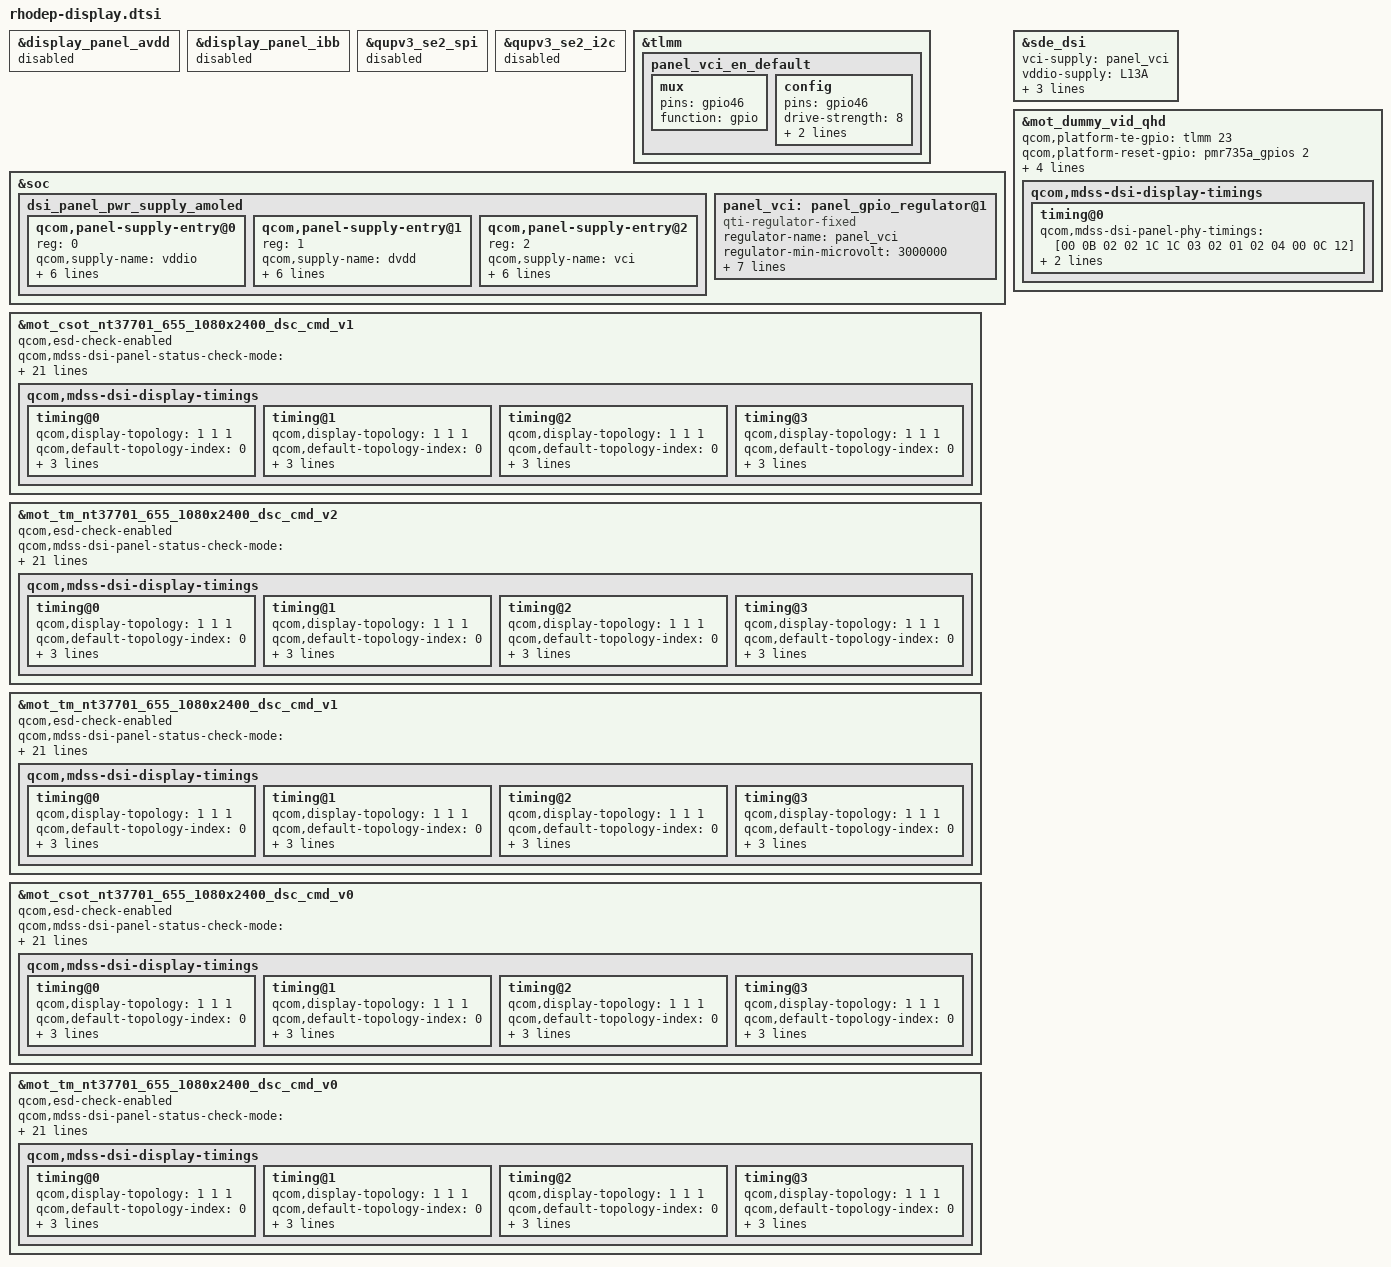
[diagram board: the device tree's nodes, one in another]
#include "dsi-panel-mot-csot-nt37701-655-1080x2400-dsc-cmd-common.dtsi"
#include "dsi-panel-mot-csot-nt37701-655-1080x2400-dsc-cmd-common-v1.dtsi"
#include "dsi-panel-mot-tianma-nt37701-655-1080x2400-dsc-cmd-common.dtsi"
#include "dsi-panel-mot-tianma-nt37701-655-1080x2400-dsc-cmd-common-v1.dtsi"
#include "dsi-panel-mot-tianma-nt37701-655-1080x2400-dsc-cmd-common-v2.dtsi"
#include "dsi-panel-mot-dummy-qhd-video.dtsi"

&display_panel_avdd {
	/delete-property/ gpio;
	/delete-property/ pinctrl-0;
};

&display_panel_avdd {
	status = "disabled";
};

&display_panel_ibb {
	status = "disabled";
};

&qupv3_se2_spi {
	status = "disabled";
};

&qupv3_se2_i2c {
	status = "disabled";
};

&tlmm {
	panel_vci_en_default: panel_vci_en_default {
		mux {
			pins = "gpio46";
			function = "gpio";
		};

		config {
			pins = "gpio46";
			drive-strength = <8>;
			bias-disable = <0>;
			output-high;
		};
	};
};

&soc {
	dsi_panel_pwr_supply_amoled: dsi_panel_pwr_supply_amoled {
		#address-cells = <1>;
		#size-cells = <0>;

		qcom,panel-supply-entry@0 {
			reg = <0>;
			qcom,supply-name = "vddio";
			qcom,supply-min-voltage = <1800000>;
			qcom,supply-max-voltage = <1800000>;
			qcom,supply-enable-load = <60700>;
			qcom,supply-disable-load = <80>;
		        qcom,supply-post-on-sleep = <2>;
			qcom,supply-post-off-sleep = <0>;
		};

		qcom,panel-supply-entry@1 {
			reg = <1>;
			qcom,supply-name = "dvdd";
			qcom,supply-min-voltage = <1250000>;
			qcom,supply-max-voltage = <1250000>;
			qcom,supply-enable-load = <60700>;
			qcom,supply-disable-load = <10>;
		        qcom,supply-post-on-sleep = <2>;
		        qcom,supply-post-off-sleep = <2>;
		};

		qcom,panel-supply-entry@2 {
			reg = <2>;
			qcom,supply-name = "vci";
			qcom,supply-min-voltage = <3000000>;
			qcom,supply-max-voltage = <3000000>;
			qcom,supply-enable-load = <30000>;
			qcom,supply-disable-load = <0>;
			qcom,supply-post-on-sleep = <0>;
			qcom,supply-post-off-sleep = <2>;
		};
	};

	panel_vci: panel_gpio_regulator@1 {
		compatible = "qti-regulator-fixed";
		regulator-name = "panel_vci";
		regulator-min-microvolt = <3000000>;
		regulator-max-microvolt = <3000000>;
		regulator-enable-ramp-delay = <233>;
		gpio = <&tlmm 46 0>;
		enable-active-high;
		regulator-boot-on;
		proxy-supply = <&panel_vci>;
		pinctrl-names = "default";
		pinctrl-0 = <&panel_vci_en_default>;
	};
};

&sde_dsi {
	/delete-property/ lab-supply;
	/delete-property/ ibb-supply;
	/delete-property/ vddio-supply;
	/delete-property/ qcom,dsi-default-panel;
	/delete-property/ avdd-supply;

	vci-supply = <&panel_vci>;
	vddio-supply = <&L13A>;
        dvdd-supply = <&L3A>;
	qcom,dsi-default-panel = <&mot_csot_nt37701_655_1080x2400_dsc_cmd_v0>;
};

&mot_csot_nt37701_655_1080x2400_dsc_cmd_v1 {
	qcom,esd-check-enabled;
	qcom,mdss-dsi-panel-status-check-mode = "te_chk_reg_rd";
	qcom,mdss-dsi-panel-status-command = [06 01 00 01 00 00 01 0a];
	qcom,mdss-dsi-panel-status-command-state = "dsi_lp_mode";
	qcom,mdss-dsi-panel-status-value = <0x9c>;
	qcom,mdss-dsi-panel-status-read-length = <1>;

	qcom,panel-supply-entries = <&dsi_panel_pwr_supply_amoled>;
	qcom,mdss-dsi-no-panel-on-read-support;
	qcom,mdss-dsi-bl-pmic-control-type = "bl_ctrl_dcs";
	qcom,mdss-dsi-bl-min-level = <9>;
	qcom,mdss-dsi-bl-max-level = <3514>;
	qcom,mdss-dsi-bl-default-level = <1757>;
	qcom,mdss-brightness-max-level = <3514>;
	qcom,platform-te-gpio = <&tlmm 23 0>;
	qcom,platform-reset-gpio = <&pmr735a_gpios 2 0>;
	qcom,bl-dsc-cmd-state = "dsi_hs_mode";

	/*qcom,mdss-dsi-panel-hdr-enabled;
	qcom,mdss-dsi-panel-hdr-color-primaries = <14950 15750 34000
	        16000 13000 35500 7000 2500>;
	qcom,mdss-dsi-panel-peak-brightness = <5000000>;
	qcom,mdss-dsi-panel-blackness-level = <100>;*/

	qcom,dsi-select-clocks = "mux_byte_clk0", "mux_pixel_clk0";

	qcom,mdss-dsi-display-timings {
		timing@0 {
			//qcom,mdss-dsi-panel-clockrate = <320000000>;
			qcom,display-topology = <1 1 1>;
			qcom,default-topology-index = <0>;
			qcom,mdss-dsi-panel-phy-drive-strength = <255>;
			qcom,mdss-dsi-panel-phy-timings = [00 0D 03 03 10 1D 04
							03 02 02 04 00 0C 08];
		};
		timing@1 {
			//qcom,mdss-dsi-panel-clockrate = <400000000>;
			qcom,display-topology = <1 1 1>;
			qcom,default-topology-index = <0>;
			qcom,mdss-dsi-panel-phy-drive-strength = <255>;
			qcom,mdss-dsi-panel-phy-timings = [00 10 03 03 11 1E 04
							04 03 02 04 00 0E 08];
		};
		timing@2 {
			//qcom,mdss-dsi-panel-clockrate = <601000000>;
			qcom,display-topology = <1 1 1>;
			qcom,default-topology-index = <0>;
			qcom,mdss-dsi-panel-phy-drive-strength = <255>;
			qcom,mdss-dsi-panel-phy-timings = [00 16 05 05 14 1F 06
							06 06 02 04 00 13 0A];
		};
		timing@3 {
			//qcom,mdss-dsi-panel-clockrate = <801000000>;
			qcom,display-topology = <1 1 1>;
			qcom,default-topology-index = <0>;
			qcom,mdss-dsi-panel-phy-drive-strength = <255>;
			qcom,mdss-dsi-panel-phy-timings = [00 1C 07 07 17 15 07
							07 08 02 04 00 18 0C];
		};
		/*timing@4 {
			//qcom,mdss-dsi-panel-clockrate = <961000000>;
			qcom,display-topology = <1 1 1>;
			qcom,default-topology-index = <0>;
			qcom,mdss-dsi-panel-phy-drive-strength = <255>;
			qcom,mdss-dsi-panel-phy-timings = [00 21 08 08 19 17 08
							08 09 02 04 00 1C 0D];
		};*/
	};
};

&mot_tm_nt37701_655_1080x2400_dsc_cmd_v2 {
	qcom,esd-check-enabled;
	qcom,mdss-dsi-panel-status-check-mode = "te_chk_reg_rd";
	qcom,mdss-dsi-panel-status-command = [06 01 00 01 00 00 01 0a];
	qcom,mdss-dsi-panel-status-command-state = "dsi_lp_mode";
	qcom,mdss-dsi-panel-status-value = <0x9c>;
	qcom,mdss-dsi-panel-status-read-length = <1>;

	qcom,panel-supply-entries = <&dsi_panel_pwr_supply_amoled>;
	qcom,mdss-dsi-no-panel-on-read-support;
	qcom,mdss-dsi-bl-pmic-control-type = "bl_ctrl_dcs";
	qcom,mdss-dsi-bl-min-level = <9>;
	qcom,mdss-dsi-bl-max-level = <3514>;
	qcom,mdss-dsi-bl-default-level = <1757>;
	qcom,mdss-brightness-max-level = <3514>;
	qcom,platform-te-gpio = <&tlmm 23 0>;
	qcom,platform-reset-gpio = <&pmr735a_gpios 2 0>;
	qcom,bl-dsc-cmd-state = "dsi_hs_mode";

	/*qcom,mdss-dsi-panel-hdr-enabled;
	qcom,mdss-dsi-panel-hdr-color-primaries = <14950 15750 34000
	        16000 13000 35500 7000 2500>;
	qcom,mdss-dsi-panel-peak-brightness = <5000000>;
	qcom,mdss-dsi-panel-blackness-level = <100>;*/

	qcom,dsi-select-clocks = "mux_byte_clk0", "mux_pixel_clk0";

	qcom,mdss-dsi-display-timings {
		timing@0 {
			//qcom,mdss-dsi-panel-clockrate = <320000000>;
			qcom,display-topology = <1 1 1>;
			qcom,default-topology-index = <0>;
			qcom,mdss-dsi-panel-phy-drive-strength = <255>;
			qcom,mdss-dsi-panel-phy-timings = [00 0D 03 03 10 1D 04
							03 02 02 04 00 0C 08];
		};
		timing@1 {
			//qcom,mdss-dsi-panel-clockrate = <400000000>;
			qcom,display-topology = <1 1 1>;
			qcom,default-topology-index = <0>;
			qcom,mdss-dsi-panel-phy-drive-strength = <255>;
			qcom,mdss-dsi-panel-phy-timings = [00 10 03 03 11 1E 04
							04 03 02 04 00 0E 08];
		};
		timing@2 {
			//qcom,mdss-dsi-panel-clockrate = <601000000>;
			qcom,display-topology = <1 1 1>;
			qcom,default-topology-index = <0>;
			qcom,mdss-dsi-panel-phy-drive-strength = <255>;
			qcom,mdss-dsi-panel-phy-timings = [00 16 05 05 14 1F 06
							06 06 02 04 00 13 0A];
		};
		timing@3 {
			//qcom,mdss-dsi-panel-clockrate = <801000000>;
			qcom,display-topology = <1 1 1>;
			qcom,default-topology-index = <0>;
			qcom,mdss-dsi-panel-phy-drive-strength = <255>;
			qcom,mdss-dsi-panel-phy-timings = [00 1C 07 07 17 15 07
							07 08 02 04 00 18 0C];
		};
		/*timing@4 {
			//qcom,mdss-dsi-panel-clockrate = <961000000>;
			qcom,display-topology = <1 1 1>;
			qcom,default-topology-index = <0>;
			qcom,mdss-dsi-panel-phy-drive-strength = <255>;
			qcom,mdss-dsi-panel-phy-timings = [00 21 08 08 19 17 08
							08 09 02 04 00 1C 0D];
		};*/
	};
};

&mot_tm_nt37701_655_1080x2400_dsc_cmd_v1 {
	qcom,esd-check-enabled;
	qcom,mdss-dsi-panel-status-check-mode = "te_chk_reg_rd";
	qcom,mdss-dsi-panel-status-command = [06 01 00 01 00 00 01 0a];
	qcom,mdss-dsi-panel-status-command-state = "dsi_lp_mode";
	qcom,mdss-dsi-panel-status-value = <0x9c>;
	qcom,mdss-dsi-panel-status-read-length = <1>;

	qcom,panel-supply-entries = <&dsi_panel_pwr_supply_amoled>;
	qcom,mdss-dsi-no-panel-on-read-support;
	qcom,mdss-dsi-bl-pmic-control-type = "bl_ctrl_dcs";
	qcom,mdss-dsi-bl-min-level = <9>;
	qcom,mdss-dsi-bl-max-level = <3514>;
	qcom,mdss-dsi-bl-default-level = <1757>;
	qcom,mdss-brightness-max-level = <3514>;
	qcom,platform-te-gpio = <&tlmm 23 0>;
	qcom,platform-reset-gpio = <&pmr735a_gpios 2 0>;
	qcom,bl-dsc-cmd-state = "dsi_hs_mode";

	/*qcom,mdss-dsi-panel-hdr-enabled;
	qcom,mdss-dsi-panel-hdr-color-primaries = <14950 15750 34000
	        16000 13000 35500 7000 2500>;
	qcom,mdss-dsi-panel-peak-brightness = <5000000>;
	qcom,mdss-dsi-panel-blackness-level = <100>;*/

	qcom,dsi-select-clocks = "mux_byte_clk0", "mux_pixel_clk0";

	qcom,mdss-dsi-display-timings {
		timing@0 {
			//qcom,mdss-dsi-panel-clockrate = <320000000>;
			qcom,display-topology = <1 1 1>;
			qcom,default-topology-index = <0>;
			qcom,mdss-dsi-panel-phy-drive-strength = <255>;
			qcom,mdss-dsi-panel-phy-timings = [00 0D 03 03 10 1D 04
							03 02 02 04 00 0C 08];
		};
		timing@1 {
			//qcom,mdss-dsi-panel-clockrate = <400000000>;
			qcom,display-topology = <1 1 1>;
			qcom,default-topology-index = <0>;
			qcom,mdss-dsi-panel-phy-drive-strength = <255>;
			qcom,mdss-dsi-panel-phy-timings = [00 10 03 03 11 1E 04
							04 03 02 04 00 0E 08];
		};
		timing@2 {
			//qcom,mdss-dsi-panel-clockrate = <601000000>;
			qcom,display-topology = <1 1 1>;
			qcom,default-topology-index = <0>;
			vqcom,mdss-dsi-panel-phy-drive-strength = <255>;
			qcom,mdss-dsi-panel-phy-timings = [00 16 05 05 14 1F 06
							06 06 02 04 00 13 0A];
		};
		timing@3 {
			//qcom,mdss-dsi-panel-clockrate = <801000000>;
			qcom,display-topology = <1 1 1>;
			qcom,default-topology-index = <0>;
			qcom,mdss-dsi-panel-phy-drive-strength = <255>;
			qcom,mdss-dsi-panel-phy-timings = [00 1C 07 07 17 15 07
							07 08 02 04 00 18 0C];
		};
		/*timing@4 {
			//qcom,mdss-dsi-panel-clockrate = <961000000>;
			qcom,display-topology = <1 1 1>;
			qcom,default-topology-index = <0>;
			qcom,mdss-dsi-panel-phy-drive-strength = <255>;
			qcom,mdss-dsi-panel-phy-timings = [00 21 08 08 19 17 08
							08 09 02 04 00 1C 0D];
		};*/
	};
};

&mot_csot_nt37701_655_1080x2400_dsc_cmd_v0 {
	qcom,esd-check-enabled;
	qcom,mdss-dsi-panel-status-check-mode = "te_chk_reg_rd";
	qcom,mdss-dsi-panel-status-command = [06 01 00 01 00 00 01 0a];
	qcom,mdss-dsi-panel-status-command-state = "dsi_lp_mode";
	qcom,mdss-dsi-panel-status-value = <0x9c>;
	qcom,mdss-dsi-panel-status-read-length = <1>;

	qcom,panel-supply-entries = <&dsi_panel_pwr_supply_amoled>;
	qcom,mdss-dsi-no-panel-on-read-support;
	qcom,mdss-dsi-bl-pmic-control-type = "bl_ctrl_dcs";
	qcom,mdss-dsi-bl-min-level = <9>;
	qcom,mdss-dsi-bl-max-level = <3514>;
	qcom,mdss-dsi-bl-default-level = <1757>;
	qcom,mdss-brightness-max-level = <3514>;
	qcom,platform-te-gpio = <&tlmm 23 0>;
	qcom,platform-reset-gpio = <&pmr735a_gpios 2 0>;
	qcom,bl-dsc-cmd-state = "dsi_hs_mode";

	/*qcom,mdss-dsi-panel-hdr-enabled;
	qcom,mdss-dsi-panel-hdr-color-primaries = <14950 15750 34000
	        16000 13000 35500 7000 2500>;
	qcom,mdss-dsi-panel-peak-brightness = <5000000>;
	qcom,mdss-dsi-panel-blackness-level = <100>;*/

	qcom,dsi-select-clocks = "mux_byte_clk0", "mux_pixel_clk0";

	qcom,mdss-dsi-display-timings {
		timing@0 {
			//qcom,mdss-dsi-panel-clockrate = <320000000>;
			qcom,display-topology = <1 1 1>;
			qcom,default-topology-index = <0>;
			qcom,mdss-dsi-panel-phy-drive-strength = <255>;
			qcom,mdss-dsi-panel-phy-timings = [00 0D 03 03 10 1D 04
							03 02 02 04 00 0C 08];
		};
		timing@1 {
			//qcom,mdss-dsi-panel-clockrate = <400000000>;
			qcom,display-topology = <1 1 1>;
			qcom,default-topology-index = <0>;
			qcom,mdss-dsi-panel-phy-drive-strength = <255>;
			qcom,mdss-dsi-panel-phy-timings = [00 10 03 03 11 1E 04
							04 03 02 04 00 0E 08];
		};
		timing@2 {
			//qcom,mdss-dsi-panel-clockrate = <601000000>;
			qcom,display-topology = <1 1 1>;
			qcom,default-topology-index = <0>;
			qcom,mdss-dsi-panel-phy-drive-strength = <255>;
			qcom,mdss-dsi-panel-phy-timings = [00 16 05 05 14 1F 06
							06 06 02 04 00 13 0A];
		};
		timing@3 {
			//qcom,mdss-dsi-panel-clockrate = <801000000>;
			qcom,display-topology = <1 1 1>;
			qcom,default-topology-index = <0>;
			qcom,mdss-dsi-panel-phy-drive-strength = <255>;
			qcom,mdss-dsi-panel-phy-timings = [00 1C 07 07 17 15 07
							07 08 02 04 00 18 0C];
		};
		/*timing@4 {
			//qcom,mdss-dsi-panel-clockrate = <961000000>;
			qcom,display-topology = <1 1 1>;
			qcom,default-topology-index = <0>;
			qcom,mdss-dsi-panel-phy-drive-strength = <255>;
			qcom,mdss-dsi-panel-phy-timings = [00 21 08 08 19 17 08
							08 09 02 04 00 1C 0D];
		};*/
	};
};

&mot_tm_nt37701_655_1080x2400_dsc_cmd_v0 {
	qcom,esd-check-enabled;
	qcom,mdss-dsi-panel-status-check-mode = "te_chk_reg_rd";
	qcom,mdss-dsi-panel-status-command = [06 01 00 01 00 00 01 0a];
	qcom,mdss-dsi-panel-status-command-state = "dsi_lp_mode";
	qcom,mdss-dsi-panel-status-value = <0x9c>;
	qcom,mdss-dsi-panel-status-read-length = <1>;

	qcom,panel-supply-entries = <&dsi_panel_pwr_supply_amoled>;
	qcom,mdss-dsi-no-panel-on-read-support;
	qcom,mdss-dsi-bl-pmic-control-type = "bl_ctrl_dcs";
	qcom,mdss-dsi-bl-min-level = <9>;
	qcom,mdss-dsi-bl-max-level = <3514>;
	qcom,mdss-dsi-bl-default-level = <1757>;
	qcom,mdss-brightness-max-level = <3514>;
	qcom,platform-te-gpio = <&tlmm 23 0>;
	qcom,platform-reset-gpio = <&pmr735a_gpios 2 0>;
	qcom,bl-dsc-cmd-state = "dsi_hs_mode";

	/*qcom,mdss-dsi-panel-hdr-enabled;
	qcom,mdss-dsi-panel-hdr-color-primaries = <14950 15750 34000
	        16000 13000 35500 7000 2500>;
	qcom,mdss-dsi-panel-peak-brightness = <5000000>;
	qcom,mdss-dsi-panel-blackness-level = <100>;*/

	qcom,dsi-select-clocks = "mux_byte_clk0", "mux_pixel_clk0";

	qcom,mdss-dsi-display-timings {
		timing@0 {
			//qcom,mdss-dsi-panel-clockrate = <320000000>;
			qcom,display-topology = <1 1 1>;
			qcom,default-topology-index = <0>;
			qcom,mdss-dsi-panel-phy-drive-strength = <255>;
			qcom,mdss-dsi-panel-phy-timings = [00 0D 03 03 10 1D 04
							03 02 02 04 00 0C 08];
		};
		timing@1 {
			//qcom,mdss-dsi-panel-clockrate = <400000000>;
			qcom,display-topology = <1 1 1>;
			qcom,default-topology-index = <0>;
			qcom,mdss-dsi-panel-phy-drive-strength = <255>;
			qcom,mdss-dsi-panel-phy-timings = [00 10 03 03 11 1E 04
							04 03 02 04 00 0E 08];
		};
		timing@2 {
			//qcom,mdss-dsi-panel-clockrate = <601000000>;
			qcom,display-topology = <1 1 1>;
			qcom,default-topology-index = <0>;
			qcom,mdss-dsi-panel-phy-drive-strength = <255>;
			qcom,mdss-dsi-panel-phy-timings = [00 16 05 05 14 1F 06
							06 06 02 04 00 13 0A];
		};
		timing@3 {
			//qcom,mdss-dsi-panel-clockrate = <801000000>;
			qcom,display-topology = <1 1 1>;
			qcom,default-topology-index = <0>;
			qcom,mdss-dsi-panel-phy-drive-strength = <255>;
			qcom,mdss-dsi-panel-phy-timings = [00 1C 07 07 17 15 07
							07 08 02 04 00 18 0C];
		};
		/*timing@4 {
			//qcom,mdss-dsi-panel-clockrate = <961000000>;
			qcom,display-topology = <1 1 1>;
			qcom,default-topology-index = <0>;
			qcom,mdss-dsi-panel-phy-drive-strength = <255>;
			qcom,mdss-dsi-panel-phy-timings = [00 21 08 08 19 17 08
							08 09 02 04 00 1C 0D];
		};*/
	};
};

&mot_dummy_vid_qhd {
	qcom,platform-te-gpio = <&tlmm 23 0>;
	qcom,platform-reset-gpio = <&pmr735a_gpios 2 0>;

	qcom,mdss-dsi-bl-pmic-control-type = "bl_ctrl_dummy";

	qcom,dsi-select-clocks = "mux_byte_clk0", "mux_pixel_clk0";

	qcom,mdss-dsi-display-timings {
		timing@0 {
			qcom,mdss-dsi-panel-phy-timings = [00 0B 02 02 1C 1C 03
							02 01 02 04 00 0C 12];
			qcom,display-topology = <1 0 1>;
			qcom,default-topology-index = <0>;
		};
	};
};

